# STM32C532xx register map
File version: 1.0
Registers are 32-bit, read-write, reset 0x0 unless marked. A register's access mark holds for its fields unless they carry their own. Offsets are from the block's base; [hi:lo] are bit positions; {n}, {i} and the like mark numbered series; 'fields as' and 'values as' point back to an identical list.

## FDCAN_CONFIG — FD Controller Area Network Configuration
Base 0x4000A500
0x00 CKDIV — FDCAN clock divider register
  [3:0] PDIV — Input Clock Divider

## USB_DRD_FS — Universal Serial Bus Full Speed Dual Role Device
Base 0x40016000
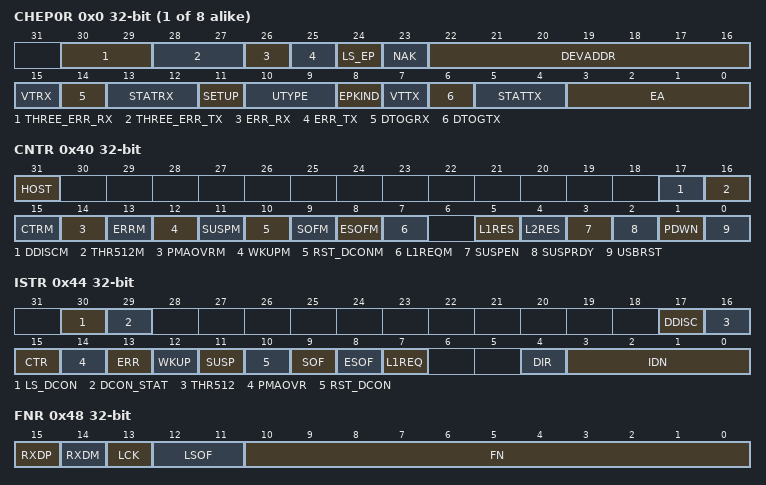
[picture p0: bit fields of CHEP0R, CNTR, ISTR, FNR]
{0x0+4i} CHEP{i}R (i=0..7) — USB Channel/Endpoint {i} register
  [30:29] THREE_ERR_RX — Three errors for an IN transaction
  [28:27] THREE_ERR_TX
  [26] ERR_RX — Received error for an IN transaction
  [25] ERR_TX
  [24] LS_EP — Low speed endpoint host with HUB only
  [23] NAK — Host mode
  [22:16] DEVADDR — Host mode
  [15] VTRX — USB valid transaction received
  [14] DTOGRX — Data Toggle, for reception transfers
  [13:12] STATRX — Status bits, for reception transfers
  [11] SETUP — Setup transaction completed
  [10:9] UTYPE — USB type of transaction
  [8] EPKIND — endpoint/channel kind
  [7] VTTX — Valid USB transaction transmitted
  [6] DTOGTX — Data toggle, for transmission transfers
  [5:4] STATTX — Status bits, for transmission transfers
  [3:0] EA — endpoint/channel address
0x40 CNTR — Control register
  [31] HOST — HOST mode
  [17] DDISCM — Device disconnection mask
  [16] THR512M — 512 byte threshold interrupt mask
  [15] CTRM — Correct transfer interrupt mask
  [14] PMAOVRM
  [13] ERRM — Error interrupt mask
  [12] WKUPM — Wake-up interrupt mask
  [11] SUSPM — Suspend mode interrupt mask
  [10] RST_DCONM
  [9] SOFM — Start of frame interrupt mask
  [8] ESOFM — Expected start of frame interrupt mask
  [7] L1REQM — LPM L1 state request interrupt mask
  [5] L1RES — L1 remote wake-up / resume driver
  [4] L2RES — L2 remote wake-up / resume driver
  [3] SUSPEN — Suspend state enable
  [2] SUSPRDY — Suspend state effective
  [1] PDWN — Power down
  [0] USBRST — USB Reset
0x44 ISTR — Interrupt status register
  [30] LS_DCON — Low speed device connected
  [29] DCON_STAT — Device connection status
  [17] DDISC — Device connection
  [16] THR512 — 512 byte threshold interrupt
  [15] CTR — Completed transfer in host mode
  [14] PMAOVR — Packet memory area over / underrun
  [13] ERR — Error
  [12] WKUP — Wake-up
  [11] SUSP — Suspend mode request
  [10] RST_DCON
  [9] SOF — Start of frame
  [8] ESOF — Expected start of frame
  [7] L1REQ — LPM L1 state request
  [4] DIR — Direction of transaction
  [3:0] IDN
0x48 FNR ro — Frame number register
  [15] RXDP — Receive data + line status
  [14] RXDM — Receive data - line status
  [13] LCK — Locked
  [12:11] LSOF — Lost SOF
  [10:0] FN — Frame number
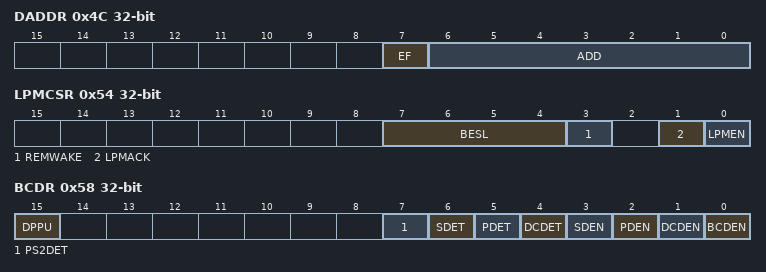
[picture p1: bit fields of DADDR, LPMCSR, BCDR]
0x4C DADDR — Device address register
  [7] EF — Enable function
  [6:0] ADD — Device address
0x54 LPMCSR — LPM Control and Status register
  [7:4] BESL — BESL value
  [3] REMWAKE — bRemoteWake value
  [1] LPMACK — LPM token acknowledge enable
  [0] LPMEN — LPM support enable
0x58 BCDR — Battery Charging detector register
  [15] DPPU
  [7] PS2DET — DM pull-up detection status
  [6] SDET — Secondary detection (SD) status
  [5] PDET — Primary detection (PD) status
  [4] DCDET — Data contact detection (DCD) status
  [3] SDEN — Secondary detection (SD) mode enable
  [2] PDEN — Primary detection (PD) mode enable
  [1] DCDEN
  [0] BCDEN — Battery charging detector (BCD) enable

## USB_DRD_PMA_BUFF — Universal Serial Bus PacketMemoryArea Buffer Descriptor Table
Base 0x40016400
0x00 TXBD — Transmission buffer address
0x04 RXBD — Reception buffer address

## LPDMA1 — DMA Controller (DMA)
Base 0x40020000
Same registers: LPDMA2 0x40021000
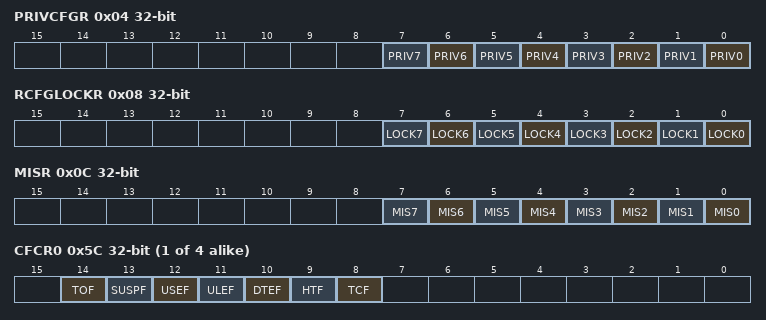
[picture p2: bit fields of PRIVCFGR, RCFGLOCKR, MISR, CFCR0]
0x04 PRIVCFGR — DMA privileged configuration register
  [n] PRIV{n} (n=0..7)
0x08 RCFGLOCKR — DMA configuration lock register
  [n] LOCK{n} (n=0..7)
0x0C MISR ro — DMA masked interrupt status register
  [n] MIS{n} (n=0..7)
{0x50+0x80*i} CLBAR{i} (i=0..3) — DMA channel x linked-list base address register
  [31:16] LBA
{0x5C+0x80*i} CFCR{i} (i=0..3) — DMA channel x flag clear register
  [14] TOF, [13] SUSPF, [12] USEF, [11] ULEF, [10] DTEF, [9] HTF, [8] TCF
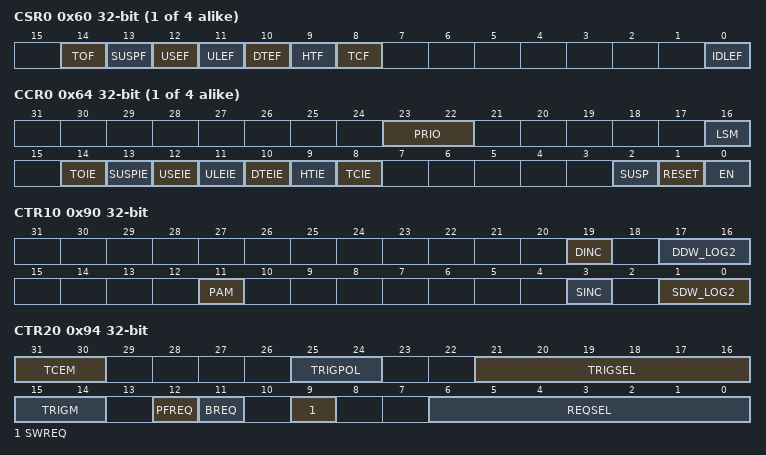
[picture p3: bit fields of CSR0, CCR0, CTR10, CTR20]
{0x60+0x80*i} CSR{i} ro (i=0..3) — DMA channel x flag status register
  [14] TOF — Trigger overrun flag
  [13] SUSPF — Completed suspension flag
  [12] USEF — User setting error flag
  [11] ULEF
  [10] DTEF — Data transfer error flag
  [9] HTF — Half transfer complete flag
  [8] TCF — Transfer complete flag
  [0] IDLEF — Idle flag
{0x64+0x80*i} CCR{i} (i=0..3) — DMA channel x control register
  [23:22] PRIO — Priority level
  [16] LSM — Link step mode
  [14] TOIE
  [13] SUSPIE
  [12] USEIE
  [11] ULEIE
  [10] DTEIE
  [9] HTIE
  [8] TCIE
  [2] SUSP — Channel suspend
  [1] RESET — Channel reset
  [0] EN — Channel enable
0x90 CTR10 — DMA channel x transfer register 1
  [19] DINC
  [17:16] DDW_LOG2
  [11] PAM — Padding / alignment mode
  [3] SINC — Source incrementing burst
  [1:0] SDW_LOG2
0x94 CTR20 — DMA channel x transfer register 2
  [31:30] TCEM
  [25:24] TRIGPOL
  [21:16] TRIGSEL
  [15:14] TRIGM — Trigger mode
  [12] PFREQ
  [11] BREQ — Block hardware request
  [9] SWREQ — Software request
  [6:0] REQSEL
0x98 CBR10 — DMA channel x block register 1
  [15:0] BNDT
{0x9C+0x80*i} CSAR{i} (i=0..3) — DMA channel x source address register
  [31:0] SA — Source Address
{0xA0+0x80*i} CDAR{i} (i=0..3) — DMA channel x destination address register
  [31:0] DA — Destination address
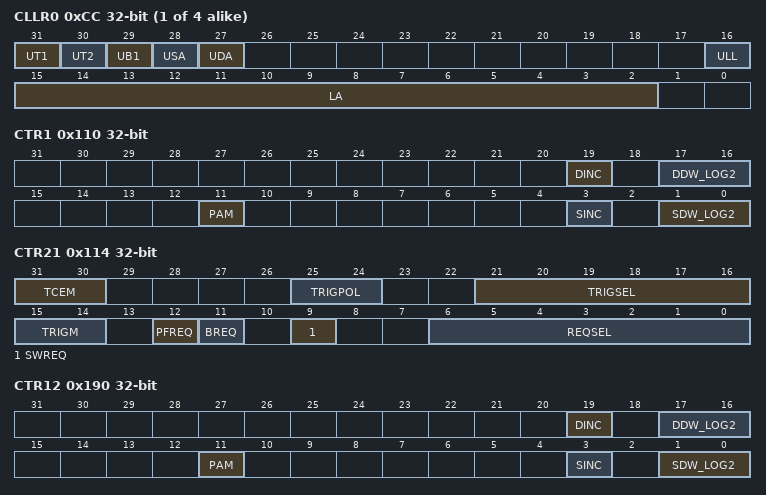
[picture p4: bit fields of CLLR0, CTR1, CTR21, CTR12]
{0xCC+0x80*i} CLLR{i} (i=0..3) — DMA channel x linked-list address register
  [31] UT1, [30] UT2, [29] UB1, [28] USA, [27] UDA, [16] ULL, [15:2] LA
0x110 CTR1 — DMA channel x transfer register 1
  fields as CTR10
0x114 CTR21 — DMA channel x transfer register 2
  fields as CTR20
0x118 CBR1 — DMA channel x block register 1
  [15:0] BNDT
0x190 CTR12 — DMA channel x transfer register 1
  fields as CTR10
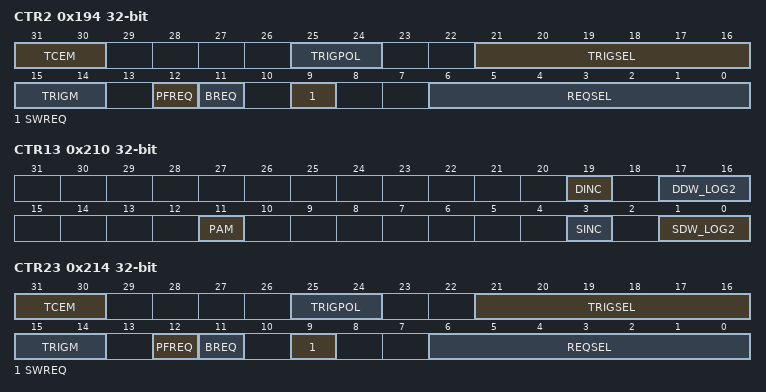
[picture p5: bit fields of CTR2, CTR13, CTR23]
0x194 CTR2 — DMA channel x transfer register 2
  fields as CTR20
0x198 CBR12 — DMA channel x block register 1
  [15:0] BNDT
0x210 CTR13 — DMA channel x transfer register 1
  fields as CTR10
0x214 CTR23 — DMA channel x transfer register 2
  fields as CTR20
0x218 CBR13 — DMA channel x block register 1
  [15:0] BNDT
